# GD32A71x register map
File version: 1.0
CPU: CM7 r2p1, little endian, MPU, FPU, DSP, 4 interrupt priority bits
Registers are 32-bit, read-write, reset 0x0 unless marked. A register's access mark holds for its fields unless they carry their own. Offsets are from the block's base; [hi:lo] are bit positions; {n}, {i} and the like mark numbered series; 'fields as' and 'values as' point back to an identical list.

## SPI0 — Serial peripheral interface
Base 0x40013000
Same registers: SPI2 0x4000E400, SPI3 0x4000E800, SPI4 0x40014400, SPI5 0x40014800, SPI1 0x40017800
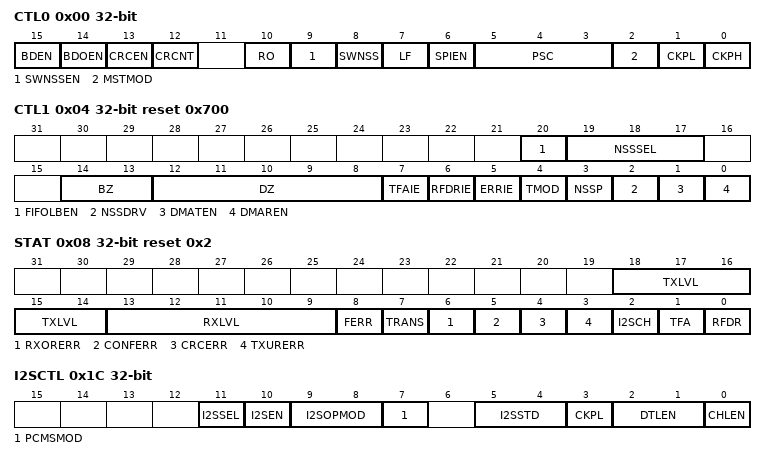
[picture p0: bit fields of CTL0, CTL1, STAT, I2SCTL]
0x00 CTL0 — Control register 0
  [15] BDEN — Bidirectional enable
  [14] BDOEN — Bidirectional transmit output enable
  [13] CRCEN — CRC calculation enable
  [12] CRCNT — CRC next transfer
  [10] RO — Receive only
  [9] SWNSSEN — NSS software mode selection
  [8] SWNSS — NSS pin selection in NSS software mode
  [7] LF — LSB first mode
  [6] SPIEN — SPI enable
  [5:3] PSC — Master clock prescaler selection
  [2] MSTMOD — Master mode enable
  [1] CKPL — Clock polarity selection
  [0] CKPH — Clock phase selection
0x04 CTL1 reset 0x700 — Control register 1
  [20] FIFOLBEN — FIFO loopback mode enable
  [19:17] NSSSEL — SPI NSS select
  [14:13] BZ — Bus access size
  [12:8] DZ — Data size
  [7] TFAIE — Transmit TXFIFO available interrupt enable
  [6] RFDRIE — Receive RXFIFO data ready interrupt enable
  [5] ERRIE — Errors interrupt enable
  [4] TMOD — SPI TI mode enable
  [3] NSSP — SPI NSS pulse mode enable
  [2] NSSDRV — Drive NSS output
  [1] DMATEN — Transmit FIFO DMA enable
  [0] DMAREN — Receive FIFO DMA enable
0x08 STAT access per field reset 0x2 — Status register
  [18:14] TXLVL ro — Transmission FIFO level
  [13:9] RXLVL ro — Receprion FIFO level
  [8] FERR rw — Format error
  [7] TRANS ro — Transmitting ongoing bit
  [6] RXORERR ro — Reception overrun error bit
  [5] CONFERR ro — SPI configuration error
  [4] CRCERR rw — SPI CRC error bit
  [3] TXURERR ro — Transmission underrun error bit
  [2] I2SCH ro — I2S channel side
  [1] TFA ro — Transmission FIFO available
  [0] RFDR ro — Reception FIFO data ready
0x0C DATA
  [31:0] DATA — Data transfer register
0x10 CRCPOLY reset 0x107 — CRC polynomial register
0x14 RCRC ro — Receive CRC register
  [31:0] RCRC — RX CRC value
0x18 TCRC ro — Transmit CRC register
  [31:0] TCRC — TX CRC value When the CRCEN bit of SPI_CTL0 is set, the hardware computes the CRC value of the transmitted bytes and saves them in TCRC register
0x1C I2SCTL — I2S control register
  [11] I2SSEL — I2S mode selection
  [10] I2SEN — I2S enable
  [9:8] I2SOPMOD — I2S operation mode
  [7] PCMSMOD — PCM frame synchronization mode
  [5:4] I2SSTD — I2S standard selection
  [3] CKPL — Idle state clock polarity
  [2:1] DTLEN — Data length
  [0] CHLEN — Channel length
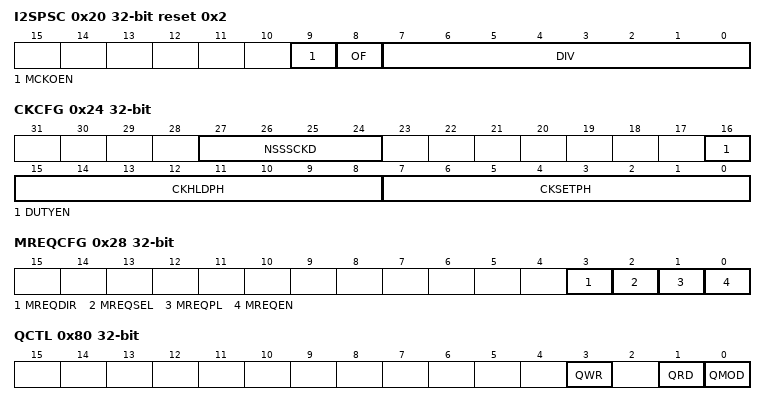
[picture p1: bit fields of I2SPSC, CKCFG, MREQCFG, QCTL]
0x20 I2SPSC reset 0x2 — I2S clock prescaler register
  [9] MCKOEN — I2S_MCK output enable
  [8] OF — Odd factor for the prescaler
  [7:0] DIV — Dividing factor for the prescaler
0x24 CKCFG — Clock configuration register
  [27:24] NSSSCKD — NSS to the first SCK edge delay
  [16] DUTYEN — SCK duty cycle enable
  [15:8] CKHLDPH — SCK hold phase
  [7:0] CKSETPH — SCK setup phase
0x28 MREQCFG — Master request configuration register
  [3] MREQDIR — MREQ pin direction
  [2] MREQSEL — Master request input source select
  [1] MREQPL — Master request polarity
  [0] MREQEN — Master request enable
0x80 QCTL — Quad-SPI mode control register
  [3] QWR — Quad-SPI mode write loopback select
  [1] QRD — Quad-SPI mode read select
  [0] QMOD — Quad-SPI mode enable

## SRAM
Base 0x49000C00
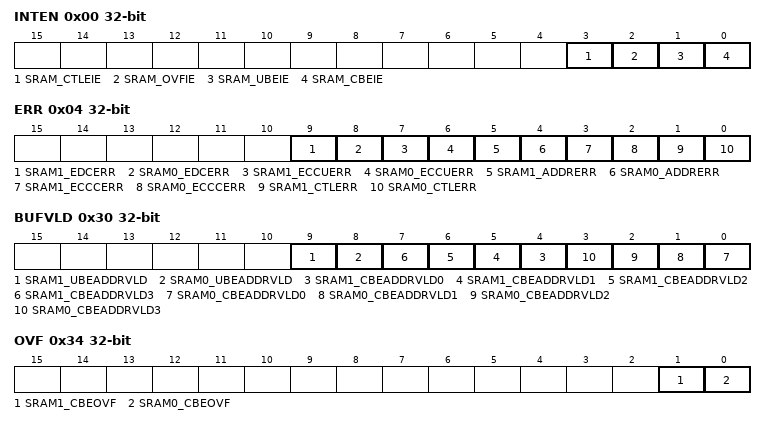
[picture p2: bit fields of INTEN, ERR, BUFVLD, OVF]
0x00 INTEN — SRAM interrupt enable register
  [3] SRAM_CTLEIE — SRAM0/1 controller redundancy check error interrupt enable
  [2] SRAM_OVFIE — SRAM0/1 address buffer overflow interrupt enable
  [1] SRAM_UBEIE — SRAM0/1 uncorrectable bit error interrupt enable
  [0] SRAM_CBEIE — SRAM0/1 correctable bit error interrupt enable
0x04 ERR — SRAM error status register
  [9] SRAM1_EDCERR — SRAM1 EDC after ECC checker error flag
  [8] SRAM0_EDCERR — SRAM0 EDC after ECC checker error flag
  [7] SRAM1_ECCUERR — SRAM1 ECC double bit uncorrectable error flag
  [6] SRAM0_ECCUERR — SRAM0 ECC double bit uncorrectable error flag
  [5] SRAM1_ADDRERR — SRAM1 ECC single bit address error flag
  [4] SRAM0_ADDRERR — SRAM0 ECC single bit address error flag
  [3] SRAM1_ECCCERR — SRAM1 ECC single bit correctable error flag
  [2] SRAM0_ECCCERR — SRAM0 ECC single bit correctable error flag
  [1] SRAM1_CTLERR — SRAM1 controller redundancy check error flag
  [0] SRAM0_CTLERR — SRAM0 controller redundancy check error flag
0x08 CBEADDR0_0 ro reset 0x24000000 — SRAM correctable bit error address 0 for SRAM_0
  [31:0] SRAM_CBEADDR0 — Record the first correctable bit error address
0x0C CBEADDR0_1 ro reset 0x24000000 — SRAM correctable bit error address 0 for SRAM_1
  fields as CBEADDR0_0
0x10 CBEADDR1_0 ro reset 0x24000000 — SRAM correctable bit error address 1 for SRAM_0
  [31:0] SRAM_CBEADDR1 — Record the second correctable bit error address
0x14 CBEADDR1_1 ro reset 0x24000000 — SRAM correctable bit error address 1 for SRAM_1
  fields as CBEADDR1_0
0x18 CBEADDR2_0 ro reset 0x24000000 — SRAM correctable bit error address 2 for SRAM_0
  [31:0] SRAM_CBEADDR2 — Record the third correctable bit error address
0x1C CBEADDR2_1 ro reset 0x24000000 — SRAM correctable bit error address 2 for SRAM_1
  fields as CBEADDR2_0
0x20 CBEADDR3_0 ro reset 0x24000000 — SRAM correctable bit error address 3 for SRAM_0
  [31:0] SRAM_CBEADDR3 — Record the fourth correctable bit error address
0x24 CBEADDR3_1 ro reset 0x24000000 — SRAM correctable bit error address 3 for SRAM_1
  fields as CBEADDR3_0
0x28 UBEADDR_0 ro reset 0x24000000 — SRAM correctable bit error address for SRAM_0
  [31:0] SRAM_UBEADDR — Record the un-correctable bit error address
0x2C UBEADDR_1 ro reset 0x24000000 — SRAM correctable bit error address for SRAM_1
  [31:0] SRAM_UBEADDR — Record the un-correctable bit error address
0x30 BUFVLD — SRAM buffer valid register
  [9] SRAM1_UBEADDRVLD — SRAM1 un-correctable bit error address valid flag
  [8] SRAM0_UBEADDRVLD — SRAM0 un-correctable bit error address valid flag
  [n+4] SRAM1_CBEADDRVLD{n} (n=0..3) — SRAM1 correctable bit error address{n} valid flag
  [n] SRAM0_CBEADDRVLD{n} (n=0..3) — SRAM0 correctable bit error address{n} valid flag
0x34 OVF — SRAM overflow status register
  [1] SRAM1_CBEOVF — SRAM1 correctable bit error address buffer overflow
  [0] SRAM0_CBEOVF — SRAM0 correctable bit error address buffer overflow
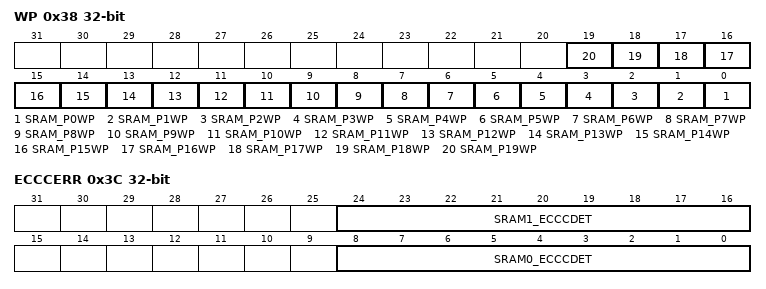
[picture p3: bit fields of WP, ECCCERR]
0x38 WP — SRAM write protection register
  [n] SRAM_P{n}WP (n=0..19) — SRAM page {n} write protection (a page granularity is 16Kbyte)
0x3C ECCCERR access per field — SRAM ECC code error status register
  [24:16] SRAM1_ECCCDET ro — SRAM1 ecc code calculated with check error detected to identify the position on a single-bit inversion
  [8:0] SRAM0_ECCCDET rw — SRAM0 ecc code calculated with check error detected to identify the position on a single-bit inversion
